# STM32H747ZIY6@M4 register map
File version: 1.0
Registers are 32-bit, access not given, reset 0x0 unless marked. A register's access mark holds for its fields unless they carry their own. Offsets are from the block's base; [hi:lo] are bit positions; {n}, {i} and the like mark numbered series; 'fields as' and 'values as' point back to an identical list.

## ETH
Base 0x40028000
0x00 MACCR
  [31] ARP, [30:29] SARC_INSADDR1, [30:28] SARC_REPADDR1, [27] IPC, [26:24] IPG, [23] GPSLCE, [22] S2KP, [21] CST, [20] ACS, [19] WD, [17] JD, [16] JE, [14] FES, [13] DM, [12] LM, [11] ECRSFD, [10] DO, [9] DCRS, [8] DR, [6:5] BL, [4] DC, [3:2] PRELEN, [1] TE, [0] RE
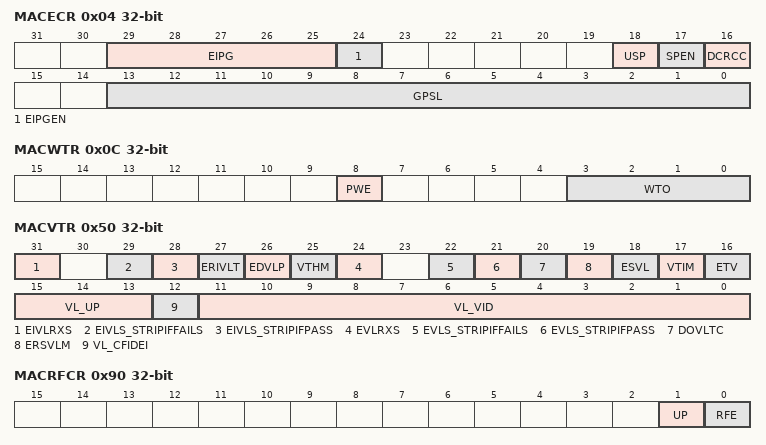
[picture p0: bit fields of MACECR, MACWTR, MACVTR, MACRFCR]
0x04 MACECR
  [29:25] EIPG, [24] EIPGEN, [18] USP, [17] SPEN, [16] DCRCC, [13:0] GPSL
0x08 MACPFR
  [31] RA, [21] DNTU, [20] IPFE, [16] VTFE, [10] HPF, [9] SAF, [8] SAIF, [7] PCF_FORWARDALL, [7:6] PCF_FORWARDPASSEDADDRFILTER, [5] DBF, [4] PM, [3] DAIF, [2] HMC, [1] HUC, [0] PR
0x0C MACWTR
  [8] PWE, [3:0] WTO
0x10 MACHT0R
0x14 MACHT1R
0x50 MACVTR
  [31] EIVLRXS, [29] EIVLS_STRIPIFFAILS, [28] EIVLS_STRIPIFPASS, [27] ERIVLT, [26] EDVLP, [25] VTHM, [24] EVLRXS, [22] EVLS_STRIPIFFAILS, [21] EVLS_STRIPIFPASS, [20] DOVLTC, [19] ERSVLM, [18] ESVL, [17] VTIM, [16] ETV, [15:13] VL_UP, [12] VL_CFIDEI, [11:0] VL_VID
0x58 MACVHTR
  [15:0] VLHT
0x60 MACVIR
  [20] VLTI, [19] CSVL, [18] VLP, [17] VLC_VLANTAGINSERT, [17:16] VLC_VLANTAGREPLACE, [15:13] VLT_UP, [12] VLT_CFIDEI, [11:0] VLT_VID
0x64 MACIVIR
  fields as MACVIR
0x70 MACTFCR
  [31:16] PT, [7] DZPQ, [6] PLT_MINUS256, [5] PLT_MINUS36, [6:4] PLT_MINUS512, [1] TFE, [0] FCB
0x90 MACRFCR
  [1] UP, [0] RFE
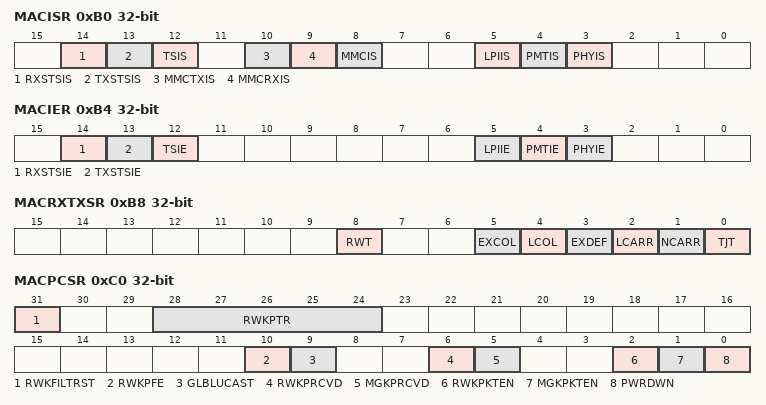
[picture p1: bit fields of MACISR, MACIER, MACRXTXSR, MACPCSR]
0xB0 MACISR
  [14] RXSTSIS, [13] TXSTSIS, [12] TSIS, [10] MMCTXIS, [9] MMCRXIS, [8] MMCIS, [5] LPIIS, [4] PMTIS, [3] PHYIS
0xB4 MACIER
  [14] RXSTSIE, [13] TXSTSIE, [12] TSIE, [5] LPIIE, [4] PMTIE, [3] PHYIE
0xB8 MACRXTXSR
  [8] RWT, [5] EXCOL, [4] LCOL, [3] EXDEF, [2] LCARR, [1] NCARR, [0] TJT
0xC0 MACPCSR
  [31] RWKFILTRST, [28:24] RWKPTR, [10] RWKPFE, [9] GLBLUCAST, [6] RWKPRCVD, [5] MGKPRCVD, [2] RWKPKTEN, [1] MGKPKTEN, [0] PWRDWN
0xC4 MACRWKPFR
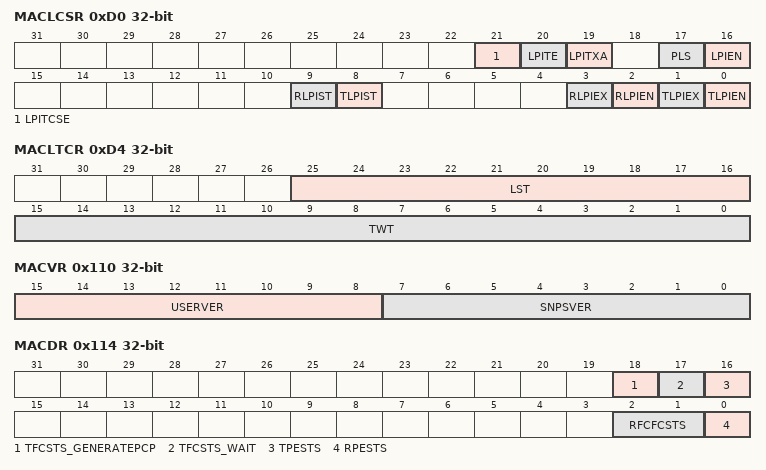
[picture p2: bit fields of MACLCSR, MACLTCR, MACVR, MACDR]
0xD0 MACLCSR
  [21] LPITCSE, [20] LPITE, [19] LPITXA, [17] PLS, [16] LPIEN, [9] RLPIST, [8] TLPIST, [3] RLPIEX, [2] RLPIEN, [1] TLPIEX, [0] TLPIEN
0xD4 MACLTCR
  [25:16] LST, [15:0] TWT
0xD8 MACLETR
  [19:0] LPIET
0xDC MAC1USTCR
  [11:0] TIC1USCNTR
0x110 MACVR
  [15:8] USERVER, [7:0] SNPSVER
0x114 MACDR
  [18] TFCSTS_GENERATEPCP, [17] TFCSTS_WAIT, [16] TPESTS, [2:1] RFCFCSTS, [0] RPESTS
0x11C MACHWF0R
  [30] ACTPHYSEL_RMII, [30:28] ACTPHYSEL_REVMII, [27] SAVLANINS, [26] TSSTSSEL_EXTERNAL, [25] TSSTSSEL_INTERNAL, [24] MACADR64SEL, [23] MACADR32SEL, [22:18] ADDMACADRSEL, [16] RXCOESEL, [14] TXCOESEL, [13] EEESEL, [12] TSSEL, [9] ARPOFFSEL, [8] MMCSEL, [7] MGKSEL, [6] RWKSEL, [5] SMASEL, [4] VLHASH, [3] PCSSEL, [2] HDSEL, [1] GMIISEL, [0] MIISEL
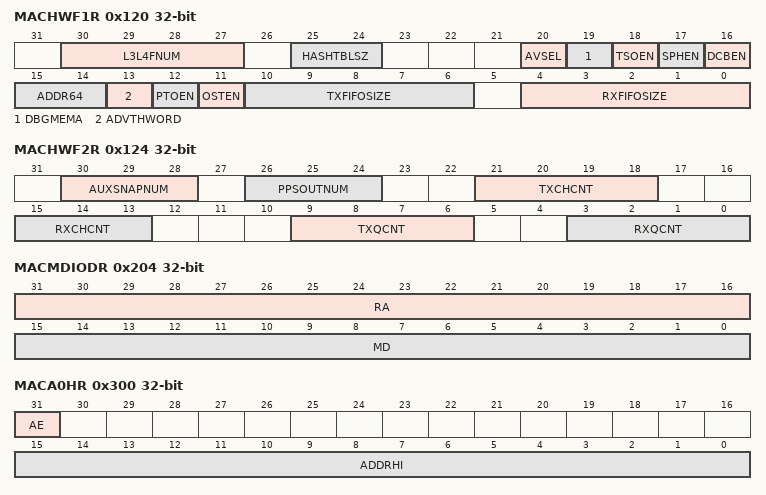
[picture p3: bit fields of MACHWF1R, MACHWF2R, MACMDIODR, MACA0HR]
0x120 MACHWF1R
  [30:27] L3L4FNUM, [25:24] HASHTBLSZ, [20] AVSEL, [19] DBGMEMA, [18] TSOEN, [17] SPHEN, [16] DCBEN, [15:14] ADDR64, [13] ADVTHWORD, [12] PTOEN, [11] OSTEN, [10:6] TXFIFOSIZE, [4:0] RXFIFOSIZE
0x124 MACHWF2R
  [30:28] AUXSNAPNUM, [26:24] PPSOUTNUM, [21:18] TXCHCNT, [15:13] RXCHCNT, [9:6] TXQCNT, [3:0] RXQCNT
0x200 MACMDIOAR
  [27] PSE, [26] BTB, [25:21] PA, [20:16] RDA, [14:12] NTC, [11] CR_DIV4AR, [11:10] CR_DIV12AR, [11:9] CR_DIV8AR, [11:8] CR_DIV6AR, [4] SKAP, [3] MOC_PRDIA, [2] MOC_WR, [1] C45E, [0] MB
0x204 MACMDIODR
  [31:16] RA, [15:0] MD
0x210 MACARPAR
  [31:0] ARPPA
0x300 MACA0HR
  [31] AE, [15:0] ADDRHI
{0x304+8i} MACA{i}LR (i=0..3)
  [31:0] ADDRLO
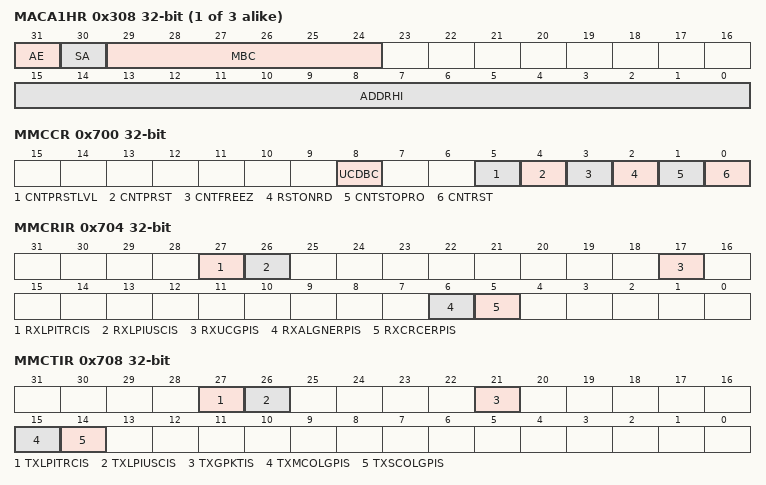
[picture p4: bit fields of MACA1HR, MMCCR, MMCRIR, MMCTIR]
{0x300+8i} MACA{i}HR (i=1..3)
  [31] AE, [30] SA, [29:24] MBC, [15:0] ADDRHI
0x700 MMCCR
  [8] UCDBC, [5] CNTPRSTLVL, [4] CNTPRST, [3] CNTFREEZ, [2] RSTONRD, [1] CNTSTOPRO, [0] CNTRST
0x704 MMCRIR
  [27] RXLPITRCIS, [26] RXLPIUSCIS, [17] RXUCGPIS, [6] RXALGNERPIS, [5] RXCRCERPIS
0x708 MMCTIR
  [27] TXLPITRCIS, [26] TXLPIUSCIS, [21] TXGPKTIS, [15] TXMCOLGPIS, [14] TXSCOLGPIS
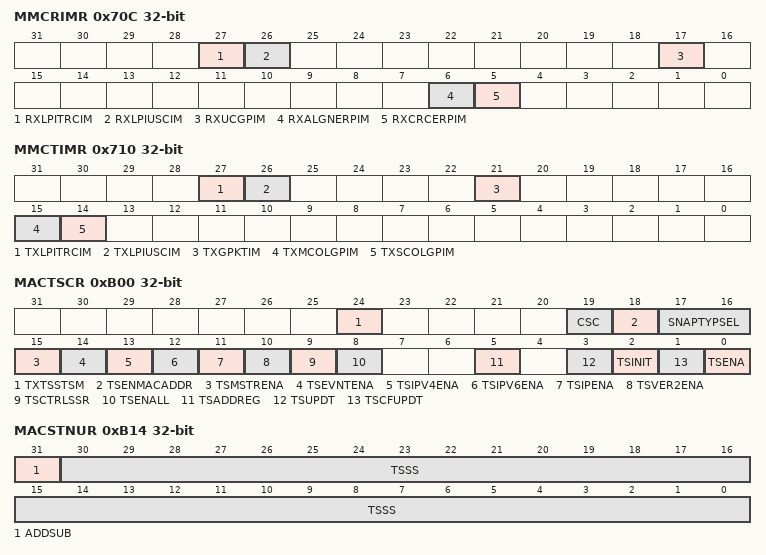
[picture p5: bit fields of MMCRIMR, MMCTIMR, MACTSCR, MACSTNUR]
0x70C MMCRIMR
  [27] RXLPITRCIM, [26] RXLPIUSCIM, [17] RXUCGPIM, [6] RXALGNERPIM, [5] RXCRCERPIM
0x710 MMCTIMR
  [27] TXLPITRCIM, [26] TXLPIUSCIM, [21] TXGPKTIM, [15] TXMCOLGPIM, [14] TXSCOLGPIM
0x74C MMCTSCGPR
0x750 MMCTMCGPR
0x768 MMCTPCGR
0x794 MMCRCRCEPR
0x798 MMCRAEPR
0x7C4 MMCRUPGR
0x7EC MMCTLPIMSTR
0x7F0 MMCTLPITCR
0x7F4 MMCRLPIMSTR
0x7F8 MMCRLPITCR
0x900 MACL3L4C0R
0x904 MACL4A0R
{0x910+4i} MACL3A{i}R0R (i=0..3)
0x930 MACL3L4C1R
0x934 MACL4A1R
{0x940+4i} MACL3A{i}R1R (i=0..3)
0xB00 MACTSCR
  [24] TXTSSTSM, [19] CSC, [18] TSENMACADDR, [17:16] SNAPTYPSEL, [15] TSMSTRENA, [14] TSEVNTENA, [13] TSIPV4ENA, [12] TSIPV6ENA, [11] TSIPENA, [10] TSVER2ENA, [9] TSCTRLSSR, [8] TSENALL, [5] TSADDREG, [3] TSUPDT, [2] TSINIT, [1] TSCFUPDT, [0] TSENA
0xB04 MACSSIR
0xB08 MACSTSR
  [31:0] TSS
0xB0C MACSTNR
  [30:0] TSSS
0xB10 MACSTSUR
  [31:0] TSS
0xB14 MACSTNUR
  [31] ADDSUB, [30:0] TSSS
0xB18 MACTSAR
  [31:0] TSAR
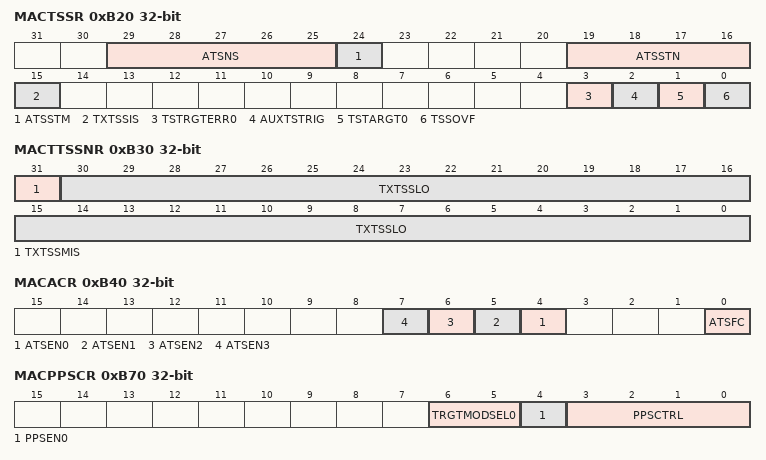
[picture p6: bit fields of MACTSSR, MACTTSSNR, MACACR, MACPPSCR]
0xB20 MACTSSR
  [29:25] ATSNS, [24] ATSSTM, [19:16] ATSSTN, [15] TXTSSIS, [3] TSTRGTERR0, [2] AUXTSTRIG, [1] TSTARGT0, [0] TSSOVF
0xB30 MACTTSSNR
  [31] TXTSSMIS, [30:0] TXTSSLO
0xB34 MACTTSSSR
  [31:0] TXTSSHI
0xB40 MACACR
  [n+4] ATSEN{n} (n=0..3), [0] ATSFC
0xB48 MACATSNR
  [30:0] AUXTSLO
0xB4C MACATSSR
  [31:0] AUXTSHI
0xB50 MACTSIACR
  [31:0] OSTIAC
0xB54 MACTSEACR
  [31:0] OSTEAC
0xB58 MACTSICNR
  [31:0] TSIC
0xB5C MACTSECNR
  [31:0] TSEC
0xB70 MACPPSCR
  [6:5] TRGTMODSEL0, [4] PPSEN0, [3:0] PPSCTRL
0xB80 MACPPSTTSR
  [31:0] TSTRH0
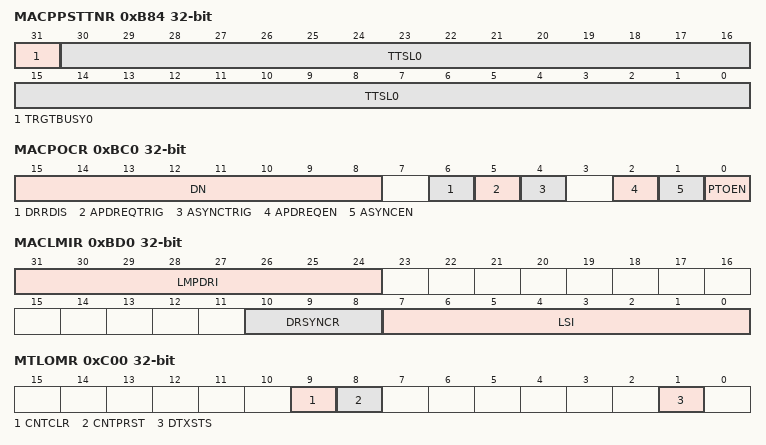
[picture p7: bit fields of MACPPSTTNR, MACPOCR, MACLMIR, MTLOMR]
0xB84 MACPPSTTNR
  [31] TRGTBUSY0, [30:0] TTSL0
0xB88 MACPPSIR
  [31:0] PPSINT0
0xB8C MACPPSWR
  [31:0] PPSWIDTH0
0xBC0 MACPOCR
  [15:8] DN, [6] DRRDIS, [5] APDREQTRIG, [4] ASYNCTRIG, [2] APDREQEN, [1] ASYNCEN, [0] PTOEN
0xBC4 MACSPI0R
  [31:0] SPI0
0xBC8 MACSPI1R
  [31:0] SPI1
0xBCC MACSPI2R
  [15:0] SPI2
0xBD0 MACLMIR
  [31:24] LMPDRI, [10:8] DRSYNCR, [7:0] LSI
0xC00 MTLOMR
  [9] CNTCLR, [8] CNTPRST, [1] DTXSTS
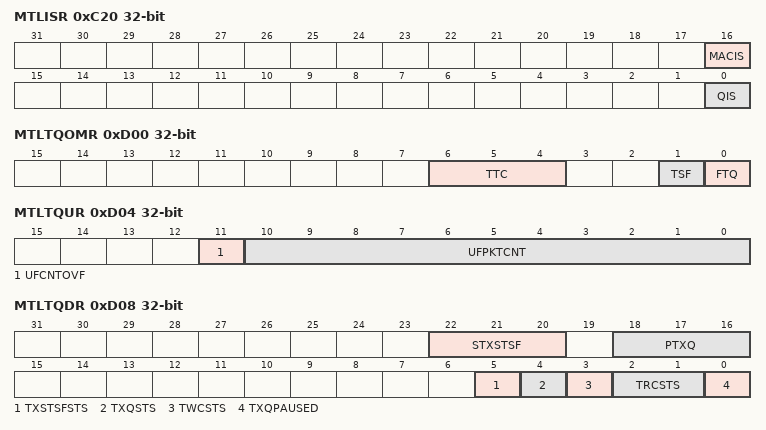
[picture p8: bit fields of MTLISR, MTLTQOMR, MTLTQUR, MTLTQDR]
0xC20 MTLISR
  [16] MACIS, [0] QIS
0xD00 MTLTQOMR
  [6:4] TTC, [1] TSF, [0] FTQ
0xD04 MTLTQUR
  [11] UFCNTOVF, [10:0] UFPKTCNT
0xD08 MTLTQDR
  [22:20] STXSTSF, [18:16] PTXQ, [5] TXSTSFSTS, [4] TXQSTS, [3] TWCSTS, [2:1] TRCSTS, [0] TXQPAUSED
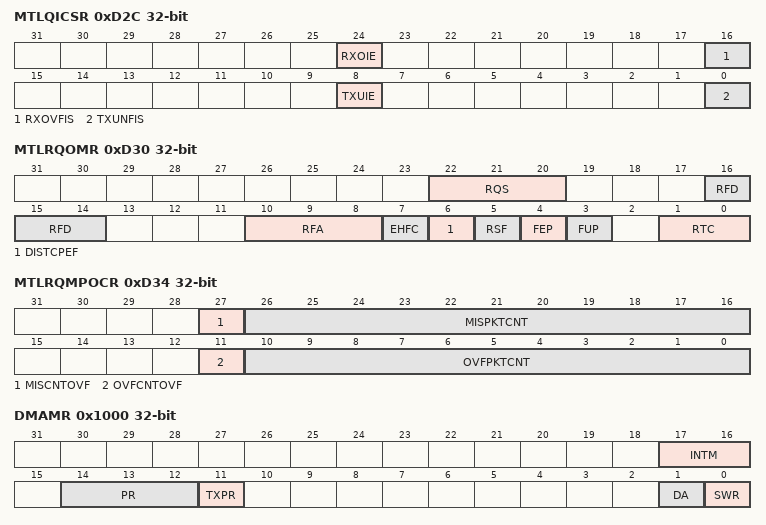
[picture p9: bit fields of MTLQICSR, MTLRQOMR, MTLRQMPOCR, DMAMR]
0xD2C MTLQICSR
  [24] RXOIE, [16] RXOVFIS, [8] TXUIE, [0] TXUNFIS
0xD30 MTLRQOMR
  [22:20] RQS, [16:14] RFD, [10:8] RFA, [7] EHFC, [6] DISTCPEF, [5] RSF, [4] FEP, [3] FUP, [1:0] RTC
0xD34 MTLRQMPOCR
  [27] MISCNTOVF, [26:16] MISPKTCNT, [11] OVFCNTOVF, [10:0] OVFPKTCNT
0xD38 MTLRQDR
  [29:16] PRXQ, [5] RXQSTS_ABOVETHRESHOLD, [5:4] RXQSTS_FULL, [2] RRCSTS_READINGSTATUS, [1] RRCSTS_READINGDATA, [0] RWCSTS
0x1000 DMAMR
  [17:16] INTM, [14:12] PR, [11] TXPR, [1] DA, [0] SWR
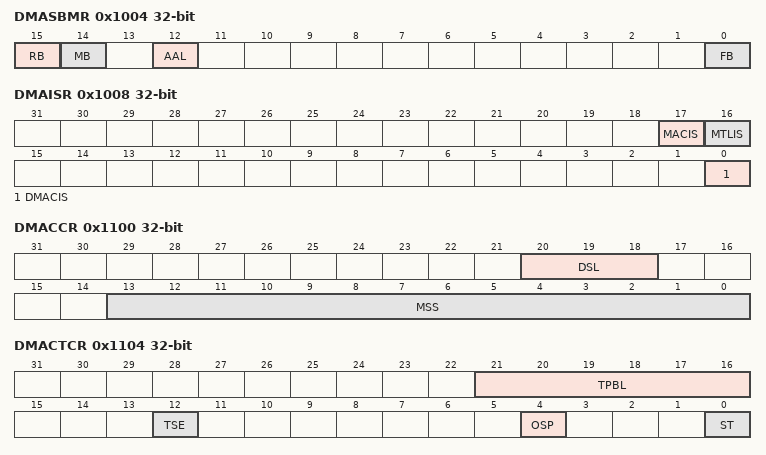
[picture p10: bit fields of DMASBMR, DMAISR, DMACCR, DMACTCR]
0x1004 DMASBMR
  [15] RB, [14] MB, [12] AAL, [0] FB
0x1008 DMAISR
  [17] MACIS, [16] MTLIS, [0] DMACIS
0x100C DMADSR
  [14] TPS_TIMESTAMP_WR, [13] TPS_WAITING, [13:12] TPS_READING, [11:8] RPS
0x1100 DMACCR
  [20:18] DSL, [13:0] MSS
0x1104 DMACTCR
  [21:16] TPBL, [12] TSE, [4] OSP, [0] ST
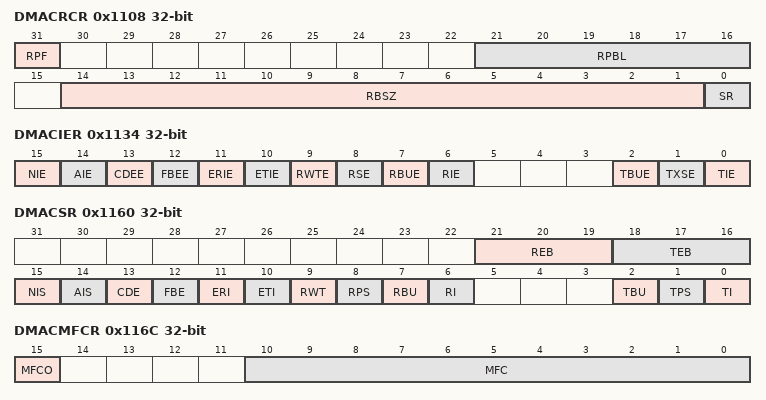
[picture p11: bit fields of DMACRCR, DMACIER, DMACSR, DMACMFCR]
0x1108 DMACRCR
  [31] RPF, [21:16] RPBL, [14:1] RBSZ, [0] SR
0x1114 DMACTDLAR
  [31:2] TDESLA
0x111C DMACRDLAR
  [31:2] RDESLA
0x1120 DMACTDTPR
  [31:2] TDT
0x1128 DMACRDTPR
  [31:2] RDT
0x112C DMACTDRLR
  [9:0] TDRL
0x1130 DMACRDRLR
  [9:0] RDRL
0x1134 DMACIER
  [15] NIE, [14] AIE, [13] CDEE, [12] FBEE, [11] ERIE, [10] ETIE, [9] RWTE, [8] RSE, [7] RBUE, [6] RIE, [2] TBUE, [1] TXSE, [0] TIE
0x1138 DMACRIWTR
  [7:0] RWT
0x113C DMACSFCSR
0x1144 DMACCATDR
  [31:0] CURTDESAPTR
0x114C DMACCARDR
  [31:0] CURRDESAPTR
0x1154 DMACCATBR
  [31:0] CURTBUFAPTR
0x115C DMACCARBR
  [31:0] CURRBUFAPTR
0x1160 DMACSR
  [21:19] REB, [18:16] TEB, [15] NIS, [14] AIS, [13] CDE, [12] FBE, [11] ERI, [10] ETI, [9] RWT, [8] RPS, [7] RBU, [6] RI, [2] TBU, [1] TPS, [0] TI
0x116C DMACMFCR
  [15] MFCO, [10:0] MFC
